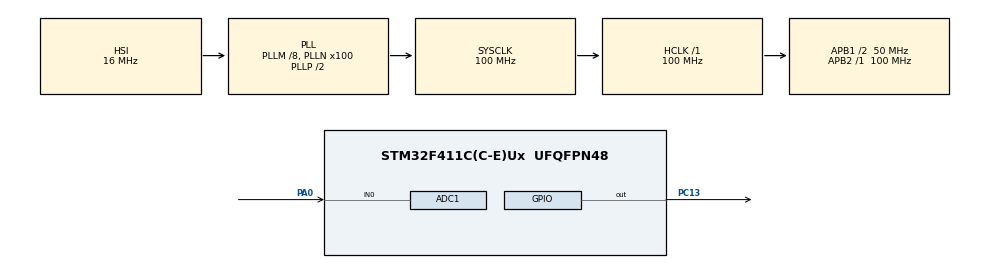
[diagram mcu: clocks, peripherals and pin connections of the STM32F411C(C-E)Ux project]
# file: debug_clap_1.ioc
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ADC1.Channel-0\#ChannelRegularConversion=ADC_CHANNEL_0
ADC1.ContinuousConvMode=ENABLE
ADC1.NbrOfConversionFlag=1
ADC1.Rank-0\#ChannelRegularConversion=1
ADC1.SamplingTime-0\#ChannelRegularConversion=ADC_SAMPLETIME_3CYCLES
ADC1.master=1
Dma.ADC1.0.Direction=DMA_PERIPH_TO_MEMORY
Dma.ADC1.0.FIFOMode=DMA_FIFOMODE_DISABLE
Dma.ADC1.0.Instance=DMA2_Stream0
Dma.ADC1.0.MemDataAlignment=DMA_MDATAALIGN_HALFWORD
Dma.ADC1.0.MemInc=DMA_MINC_ENABLE
Dma.ADC1.0.Mode=DMA_CIRCULAR
Dma.ADC1.0.PeriphDataAlignment=DMA_PDATAALIGN_HALFWORD
Dma.ADC1.0.PeriphInc=DMA_PINC_DISABLE
Dma.ADC1.0.Priority=DMA_PRIORITY_LOW
Dma.Request0=ADC1
Mcu.Family=STM32F4
Mcu.Name=STM32F411C(C-E)Ux
Mcu.Package=UFQFPN48
NVIC.DMA2_Stream0_IRQn=true\:0\:0\:false\:false\:true\:false\:true\:true
NVIC.PriorityGroup=NVIC_PRIORITYGROUP_4
PA0-WKUP.Signal=ADCx_IN0
PA13.Mode=Trace_Asynchronous_SW
PA13.Signal=SYS_JTMS-SWDIO
PA14.Mode=Trace_Asynchronous_SW
PA14.Signal=SYS_JTCK-SWCLK
PB3.Mode=Trace_Asynchronous_SW
PB3.Signal=SYS_JTDO-SWO
PC13-ANTI_TAMP.Signal=GPIO_Output
PH0\ -\ OSC_IN.Mode=HSE-External-Oscillator
PH0\ -\ OSC_IN.Signal=RCC_OSC_IN
PH1\ -\ OSC_OUT.Mode=HSE-External-Oscillator
PH1\ -\ OSC_OUT.Signal=RCC_OSC_OUT
ProjectManager.HeapSize=0x200
ProjectManager.StackSize=0x400
ProjectManager.TargetToolchain=STM32CubeIDE
RCC.48MHZClocksFreq_Value=50000000
RCC.AHBFreq_Value=100000000
RCC.APB1CLKDivider=RCC_HCLK_DIV2
RCC.APB1Freq_Value=50000000
RCC.APB1TimFreq_Value=100000000
RCC.APB2Freq_Value=100000000
RCC.APB2TimFreq_Value=100000000
RCC.CortexFreq_Value=100000000
RCC.HCLKFreq_Value=100000000
RCC.HSE_VALUE=25000000
RCC.HSI_VALUE=16000000
RCC.LSE_VALUE=32768
RCC.PLLM=8
RCC.PLLN=100
RCC.SYSCLKFreq_VALUE=100000000
RCC.SYSCLKSource=RCC_SYSCLKSOURCE_PLLCLK
RCC.VCOOutputFreq_Value=200000000
SH.ADCx_IN0.0=ADC1_IN0,IN0
TIM2.Prescaler=10-1
TIM3.Prescaler=10000-1
TIM4.Prescaler=10000-1
VP_TIM2_VS_ClockSourceINT.Mode=Internal
VP_TIM3_VS_ClockSourceINT.Mode=Internal
VP_TIM4_VS_ClockSourceINT.Mode=Internal
board=custom

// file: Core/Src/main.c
/* USER CODE BEGIN Header */
/**
  ******************************************************************************
  * @file           : main.c
  * @brief          : Main program body
  ******************************************************************************
  * @attention
  *
  * Copyright (c) 2023 STMicroelectronics.
  * All rights reserved.
  *
  * This software is licensed under terms that can be found in the LICENSE file
  * in the root directory of this software component.
  * If no LICENSE file comes with this software, it is provided AS-IS.
  *
  ******************************************************************************
  */
/* USER CODE END Header */
#include "main.h"

/* USER CODE BEGIN Includes */
#include <stdio.h>
#include<math.h>
#include<stdbool.h>
#include<stdlib.h>
#include<stdint.h>
#include "pre_modify.h"
#include "fft_funs.h"
/* USER CODE END Includes */

ADC_HandleTypeDef hadc1;
DMA_HandleTypeDef hdma_adc1;

TIM_HandleTypeDef htim2;
TIM_HandleTypeDef htim3;
TIM_HandleTypeDef htim4;

/* USER CODE BEGIN PV */

uint32_t adc_val;
uint8_t flag_loud_first;
uint8_t flag_loud_second;

float data_re_first[SAMPLE];
float data_im_first[SAMPLE];
float data_re_second[SAMPLE];
float data_im_second[SAMPLE];

/* USER CODE END PV */

void SystemClock_Config(void);
static void MX_GPIO_Init(void);
static void MX_DMA_Init(void);
static void MX_TIM2_Init(void);
static void MX_ADC1_Init(void);
static void MX_TIM3_Init(void);
static void MX_TIM4_Init(void);
/* USER CODE BEGIN PFP */

void run_while();

/* USER CODE END PFP */

int main(void)
{

  /* MCU Configuration--------------------------------------------------------*/

  /* Reset of all peripherals, Initializes the Flash interface and the Systick. */
  HAL_Init();

  /* Configure the system clock */
  SystemClock_Config();

  /* Initialize all configured peripherals */
  MX_GPIO_Init();
  MX_DMA_Init();
  MX_TIM2_Init();
  MX_ADC1_Init();
  MX_TIM3_Init();
  MX_TIM4_Init();

  /* Infinite loop */
  /* USER CODE BEGIN WHILE */
  /*Start time  */
  HAL_TIM_Base_Start(&htim2);
  HAL_TIM_Base_Start(&htim3);
  HAL_TIM_Base_Start(&htim4);
  HAL_ADC_Start_DMA(&hadc1,&adc_val,1);

  HAL_GPIO_WritePin(GPIOC, GPIO_PIN_13,1);//turn off led
  HAL_Delay(1000);

  while (1)
  {
	run_while();

    /* USER CODE END WHILE */

  }
}

void SystemClock_Config(void)
{
  RCC_OscInitTypeDef RCC_OscInitStruct = {0};
  RCC_ClkInitTypeDef RCC_ClkInitStruct = {0};

  /** Configure the main internal regulator output voltage
  */
  __HAL_RCC_PWR_CLK_ENABLE();
  __HAL_PWR_VOLTAGESCALING_CONFIG(PWR_REGULATOR_VOLTAGE_SCALE1);

  /** Initializes the RCC Oscillators according to the specified parameters
  * in the RCC_OscInitTypeDef structure.
  */
  RCC_OscInitStruct.OscillatorType = RCC_OSCILLATORTYPE_HSI;
  RCC_OscInitStruct.HSIState = RCC_HSI_ON;
  RCC_OscInitStruct.HSICalibrationValue = RCC_HSICALIBRATION_DEFAULT;
  RCC_OscInitStruct.PLL.PLLState = RCC_PLL_ON;
  RCC_OscInitStruct.PLL.PLLSource = RCC_PLLSOURCE_HSI;
  RCC_OscInitStruct.PLL.PLLM = 8;
  RCC_OscInitStruct.PLL.PLLN = 100;
  RCC_OscInitStruct.PLL.PLLP = RCC_PLLP_DIV2;
  RCC_OscInitStruct.PLL.PLLQ = 4;
  if (HAL_RCC_OscConfig(&RCC_OscInitStruct) != HAL_OK)
  {
    Error_Handler();
  }

  /** Initializes the CPU, AHB and APB buses clocks
  */
  RCC_ClkInitStruct.ClockType = RCC_CLOCKTYPE_HCLK|RCC_CLOCKTYPE_SYSCLK
                              |RCC_CLOCKTYPE_PCLK1|RCC_CLOCKTYPE_PCLK2;
  RCC_ClkInitStruct.SYSCLKSource = RCC_SYSCLKSOURCE_PLLCLK;
  RCC_ClkInitStruct.AHBCLKDivider = RCC_SYSCLK_DIV1;
  RCC_ClkInitStruct.APB1CLKDivider = RCC_HCLK_DIV2;
  RCC_ClkInitStruct.APB2CLKDivider = RCC_HCLK_DIV1;

  if (HAL_RCC_ClockConfig(&RCC_ClkInitStruct, FLASH_LATENCY_3) != HAL_OK)
  {
    Error_Handler();
  }
}

static void MX_ADC1_Init(void)
{

  ADC_ChannelConfTypeDef sConfig = {0};

  /** Configure the global features of the ADC (Clock, Resolution, Data Alignment and number of conversion)
  */
  hadc1.Instance = ADC1;
  hadc1.Init.ClockPrescaler = ADC_CLOCK_SYNC_PCLK_DIV4;
  hadc1.Init.Resolution = ADC_RESOLUTION_12B;
  hadc1.Init.ScanConvMode = DISABLE;
  hadc1.Init.ContinuousConvMode = DISABLE;
  hadc1.Init.DiscontinuousConvMode = DISABLE;
  hadc1.Init.ExternalTrigConvEdge = ADC_EXTERNALTRIGCONVEDGE_NONE;
  hadc1.Init.ExternalTrigConv = ADC_SOFTWARE_START;
  hadc1.Init.DataAlign = ADC_DATAALIGN_RIGHT;
  hadc1.Init.NbrOfConversion = 1;
  hadc1.Init.DMAContinuousRequests = DISABLE;
  hadc1.Init.EOCSelection = ADC_EOC_SINGLE_CONV;
  if (HAL_ADC_Init(&hadc1) != HAL_OK)
  {
    Error_Handler();
  }

  /** Configure for the selected ADC regular channel its corresponding rank in the sequencer and its sample time.
  */
  sConfig.Channel = ADC_CHANNEL_0;
  sConfig.Rank = 1;
  sConfig.SamplingTime = ADC_SAMPLETIME_3CYCLES;
  if (HAL_ADC_ConfigChannel(&hadc1, &sConfig) != HAL_OK)
  {
    Error_Handler();
  }

}

static void MX_TIM2_Init(void)
{

  TIM_ClockConfigTypeDef sClockSourceConfig = {0};
  TIM_MasterConfigTypeDef sMasterConfig = {0};

  htim2.Instance = TIM2;
  htim2.Init.Prescaler = 10-1;
  htim2.Init.CounterMode = TIM_COUNTERMODE_UP;
  htim2.Init.Period = 4294967295;
  htim2.Init.ClockDivision = TIM_CLOCKDIVISION_DIV1;
  htim2.Init.AutoReloadPreload = TIM_AUTORELOAD_PRELOAD_DISABLE;
  if (HAL_TIM_Base_Init(&htim2) != HAL_OK)
  {
    Error_Handler();
  }
  sClockSourceConfig.ClockSource = TIM_CLOCKSOURCE_INTERNAL;
  if (HAL_TIM_ConfigClockSource(&htim2, &sClockSourceConfig) != HAL_OK)
  {
    Error_Handler();
  }
  sMasterConfig.MasterOutputTrigger = TIM_TRGO_RESET;
  sMasterConfig.MasterSlaveMode = TIM_MASTERSLAVEMODE_DISABLE;
  if (HAL_TIMEx_MasterConfigSynchronization(&htim2, &sMasterConfig) != HAL_OK)
  {
    Error_Handler();
  }

}

static void MX_TIM3_Init(void)
{

  TIM_ClockConfigTypeDef sClockSourceConfig = {0};
  TIM_MasterConfigTypeDef sMasterConfig = {0};

  htim3.Instance = TIM3;
  htim3.Init.Prescaler = 10000-1;
  htim3.Init.CounterMode = TIM_COUNTERMODE_UP;
  htim3.Init.Period = 65535;
  htim3.Init.ClockDivision = TIM_CLOCKDIVISION_DIV1;
  htim3.Init.AutoReloadPreload = TIM_AUTORELOAD_PRELOAD_DISABLE;
  if (HAL_TIM_Base_Init(&htim3) != HAL_OK)
  {
    Error_Handler();
  }
  sClockSourceConfig.ClockSource = TIM_CLOCKSOURCE_INTERNAL;
  if (HAL_TIM_ConfigClockSource(&htim3, &sClockSourceConfig) != HAL_OK)
  {
    Error_Handler();
  }
  sMasterConfig.MasterOutputTrigger = TIM_TRGO_RESET;
  sMasterConfig.MasterSlaveMode = TIM_MASTERSLAVEMODE_DISABLE;
  if (HAL_TIMEx_MasterConfigSynchronization(&htim3, &sMasterConfig) != HAL_OK)
  {
    Error_Handler();
  }

}

static void MX_TIM4_Init(void)
{

  TIM_ClockConfigTypeDef sClockSourceConfig = {0};
  TIM_MasterConfigTypeDef sMasterConfig = {0};

  htim4.Instance = TIM4;
  htim4.Init.Prescaler = 10000-1;
  htim4.Init.CounterMode = TIM_COUNTERMODE_UP;
  htim4.Init.Period = 65535;
  htim4.Init.ClockDivision = TIM_CLOCKDIVISION_DIV1;
  htim4.Init.AutoReloadPreload = TIM_AUTORELOAD_PRELOAD_DISABLE;
  if (HAL_TIM_Base_Init(&htim4) != HAL_OK)
  {
    Error_Handler();
  }
  sClockSourceConfig.ClockSource = TIM_CLOCKSOURCE_INTERNAL;
  if (HAL_TIM_ConfigClockSource(&htim4, &sClockSourceConfig) != HAL_OK)
  {
    Error_Handler();
  }
  sMasterConfig.MasterOutputTrigger = TIM_TRGO_RESET;
  sMasterConfig.MasterSlaveMode = TIM_MASTERSLAVEMODE_DISABLE;
  if (HAL_TIMEx_MasterConfigSynchronization(&htim4, &sMasterConfig) != HAL_OK)
  {
    Error_Handler();
  }

}

static void MX_DMA_Init(void)
{

  /* DMA controller clock enable */
  __HAL_RCC_DMA2_CLK_ENABLE();

  /* DMA interrupt init */
  /* DMA2_Stream0_IRQn interrupt configuration */
  HAL_NVIC_SetPriority(DMA2_Stream0_IRQn, 0, 0);
  HAL_NVIC_EnableIRQ(DMA2_Stream0_IRQn);

}

static void MX_GPIO_Init(void)
{
  GPIO_InitTypeDef GPIO_InitStruct = {0};

  /* GPIO Ports Clock Enable */
  __HAL_RCC_GPIOC_CLK_ENABLE();
  __HAL_RCC_GPIOH_CLK_ENABLE();
  __HAL_RCC_GPIOA_CLK_ENABLE();
  __HAL_RCC_GPIOB_CLK_ENABLE();

  /*Configure GPIO pin Output Level */
  HAL_GPIO_WritePin(GPIOC, GPIO_PIN_13, GPIO_PIN_RESET);

  /*Configure GPIO pin : PC13 */
  GPIO_InitStruct.Pin = GPIO_PIN_13;
  GPIO_InitStruct.Mode = GPIO_MODE_OUTPUT_PP;
  GPIO_InitStruct.Pull = GPIO_NOPULL;
  GPIO_InitStruct.Speed = GPIO_SPEED_FREQ_LOW;
  HAL_GPIO_Init(GPIOC, &GPIO_InitStruct);

}

/* USER CODE BEGIN 4 */

void run_while()
{
	uint8_t count_sample=SAMPLE,index=0;
//	mean_
	/* data_im array before fft calculation is always =0*/
	while(1)
	{
		if(__HAL_TIM_GET_COUNTER(&htim2)>INTERVAL_SAMPLE)
		{
			if (index==count_sample )
			{
				break;
			}

			/*read SAMPLE/2 values (ADC) and store to data_re_fisrt  */
			__HAL_TIM_SET_COUNTER(&htim2,0);
			HAL_ADC_Start_DMA(&hadc1,&adc_val,1);
			const float map_adc_val=(float)map(adc_val,0,4095,MIN_AMP,MAX_AMP);

//			mean_amp_second+= abs(map_adc_val);
			data_re_second[index]=map_adc_val;
			data_im_second[index]=0;
			if (abs(map_adc_val)>AMP_THRESHOLD)
			{
				flag_loud_second=1;
			}

			if (index<HALF_SAMPLE)
			{
				/*store adc_val in second half data_re_first */

//				mean_amp_first+=abs(map_adc_val);
				data_re_first[HALF_SAMPLE+index]=map_adc_val;
				data_im_first[HALF_SAMPLE+index]=0;
				if (abs(map_adc_val)>AMP_THRESHOLD)
				{
					flag_loud_first =1;
				}

			}
			if (index>=HALF_SAMPLE)
			{
				if (abs(map_adc_val)>AMP_THRESHOLD)
				{
					flag_loud_first=1;
				}

				/*store adc_val in first half data_re_first */
//				mean_amp_first+= abs(map_adc_val);
				data_re_first[index-HALF_SAMPLE]=map_adc_val;
				data_im_first[index-HALF_SAMPLE]=0;
			}
			if (index==SAMPLE/2)
			{
				if (flag_loud_first==1)
				{
					fft(data_re_first,data_im_first,SAMPLE);
					const uint8_t argmax_first=argmax_fft(data_re_first,data_im_first,SAMPLE);
//					const uint32_t value= sqrt(pow(data_re_second[argmax_first],2)+pow(data_im_second[argmax_first],2));
//					printf("1          %d                  %lu\n ",argmax_first,value);
					if (argmax_first==FREQ_INDEX)
					{
						if (__HAL_TIM_GET_COUNTER(&htim4)>500)
						{
							/*avoid led on off continuously, delay 50 ms, prescaler of tim4=10000-1 */
							__HAL_TIM_SET_COUNTER(&htim4,0);
							HAL_GPIO_TogglePin(GPIOC, GPIO_PIN_13);
//							printf("1      clap detect   %f\n",mean_amp_first/SAMPLE );
						}

//

					}

				}
//				mean_amp_first=0;
				flag_loud_first=0;

			}

			index++;
		}
	}
	/*index =count_sample */
	if (flag_loud_second==1)
	{
		fft(data_re_second,data_im_second,SAMPLE);
		const uint8_t argmax_second=argmax_fft(data_re_second,data_im_second,SAMPLE);
//		const uint32_t value= sqrt(pow(data_re_second[argmax_second],2)+pow(data_im_second[argmax_second],2));
//		printf("1          %d               %lu\n",argmax_second, value);
		if (argmax_second==FREQ_INDEX)
		{
			if (__HAL_TIM_GET_COUNTER(&htim4)>500)
			{
				/*avoid led on off continuously, delay 100 ms, prescaler of tim4=10000-1  */
				__HAL_TIM_SET_COUNTER(&htim4,0);
				HAL_GPIO_TogglePin(GPIOC, GPIO_PIN_13);
//							printf("2      clap detect      %f\n",mean_amp_second/SAMPLE);
			}

		}
	}
//	mean_amp_second=0;
	flag_loud_second=0;
}

/* USER CODE END 4 */

void Error_Handler(void)
{
  __disable_irq();
  while (1)
  {
  }
}
